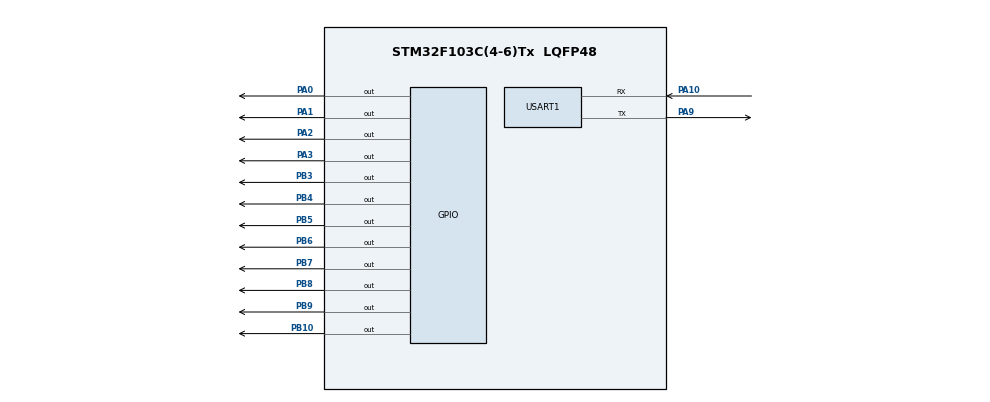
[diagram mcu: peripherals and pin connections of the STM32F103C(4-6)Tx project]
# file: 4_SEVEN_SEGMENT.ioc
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Mcu.Family=STM32F1
Mcu.Name=STM32F103C(4-6)Tx
Mcu.Package=LQFP48
NVIC.PriorityGroup=NVIC_PRIORITYGROUP_4
PA0-WKUP.Signal=GPIO_Output
PA1.Signal=GPIO_Output
PA10.Mode=Asynchronous
PA10.Signal=USART1_RX
PA2.Signal=GPIO_Output
PA3.Signal=GPIO_Output
PA9.Mode=Asynchronous
PA9.Signal=USART1_TX
PB10.Signal=GPIO_Output
PB3.Signal=GPIO_Output
PB4.Signal=GPIO_Output
PB5.Signal=GPIO_Output
PB6.Signal=GPIO_Output
PB7.Signal=GPIO_Output
PB8.Signal=GPIO_Output
PB9.Signal=GPIO_Output
PD0-OSC_IN.Mode=HSE-External-Oscillator
PD0-OSC_IN.Signal=RCC_OSC_IN
PD1-OSC_OUT.Mode=HSE-External-Oscillator
PD1-OSC_OUT.Signal=RCC_OSC_OUT
ProjectManager.HeapSize=0x200
ProjectManager.StackSize=0x400
ProjectManager.TargetToolchain=STM32CubeIDE
RCC.APB1Freq_Value=8000000
RCC.APB2Freq_Value=8000000
USART1.VirtualMode=VM_ASYNC
board=custom

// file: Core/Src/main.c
/* USER CODE BEGIN Header */
/**
  ******************************************************************************
  * @file           : main.c
  * @brief          : Main program body
  ******************************************************************************
  * @attention
  *
  * Copyright (c) 2023 STMicroelectronics.
  * All rights reserved.
  *
  * This software is licensed under terms that can be found in the LICENSE file
  * in the root directory of this software component.
  * If no LICENSE file comes with this software, it is provided AS-IS.
  *
  ******************************************************************************
  */
/* USER CODE END Header */
#include "main.h"

UART_HandleTypeDef huart1;

void SystemClock_Config(void);
static void MX_GPIO_Init(void);
static void MX_USART1_UART_Init(void);

int main(void)
{

  /* MCU Configuration--------------------------------------------------------*/

  /* Reset of all peripherals, Initializes the Flash interface and the Systick. */
  HAL_Init();

  /* USER CODE BEGIN Init */
/*
  GPIO_InitTypeDef GPIO_InitStruct;
      __HAL_RCC_GPIOA_CLK_ENABLE();
      __HAL_RCC_GPIOB_CLK_ENABLE();
      GPIO_InitStruct.Pin = GPIO_PIN_0 | GPIO_PIN_1 | GPIO_PIN_2 | GPIO_PIN_3;
      GPIO_InitStruct.Mode = GPIO_MODE_OUTPUT_PP;
      GPIO_InitStruct.Speed = GPIO_SPEED_FREQ_HIGH;
      HAL_GPIO_Init(GPIOA, &GPIO_InitStruct);
      GPIO_InitStruct.Pin = GPIO_PIN_3 | GPIO_PIN_4 | GPIO_PIN_5 | GPIO_PIN_6
              | GPIO_PIN_7 | GPIO_PIN_8 | GPIO_PIN_9 | GPIO_PIN_10;
      GPIO_InitStruct.Mode = GPIO_MODE_OUTPUT_PP;
      GPIO_InitStruct.Speed = GPIO_SPEED_FREQ_HIGH;
      HAL_GPIO_Init(GPIOB, &GPIO_InitStruct);
      */
  /* USER CODE END Init */

  /* Configure the system clock */
  SystemClock_Config();

  /* Initialize all configured peripherals */
  MX_GPIO_Init();
  MX_USART1_UART_Init();

  /* Infinite loop */
  while (1)
  {
	  displayNumber(1861);
	  HAL_Delay(500);
	  //displayNumber(5678);
	  //HAL_Delay(500);

	          //displayNumber(5678);
	          //HAL_Delay(1000);
  }
}

void displayDigit(int digit, int value)
{
    switch (digit)
    {
    case 1:
        HAL_GPIO_WritePin(GPIOA, GPIO_PIN_0, GPIO_PIN_SET);
        HAL_Delay(1000);
        break;
    case 2:
        HAL_GPIO_WritePin(GPIOA, GPIO_PIN_1, GPIO_PIN_SET);
        HAL_Delay(1000);

        break;
    case 3:
        HAL_GPIO_WritePin(GPIOA, GPIO_PIN_2, GPIO_PIN_SET);
        HAL_Delay(1000);

        break;
    case 4:
        HAL_GPIO_WritePin(GPIOA, GPIO_PIN_3, GPIO_PIN_SET);
        HAL_Delay(1000);

        break;
    }
    switch (value)
    {
    case 0:
        HAL_GPIO_WritePin(GPIOB,
                GPIO_PIN_3 | GPIO_PIN_4 | GPIO_PIN_5 | GPIO_PIN_6 | GPIO_PIN_7
                        | GPIO_PIN_8, GPIO_PIN_SET);
        HAL_GPIO_WritePin(GPIOB, GPIO_PIN_9 | GPIO_PIN_10, GPIO_PIN_RESET);
        break;
    case 1:
        HAL_GPIO_WritePin(GPIOB, GPIO_PIN_4 | GPIO_PIN_5, GPIO_PIN_SET);
        HAL_GPIO_WritePin(GPIOB,
                GPIO_PIN_3 | GPIO_PIN_6 | GPIO_PIN_8 | GPIO_PIN_7 | GPIO_PIN_9
                        | GPIO_PIN_10, GPIO_PIN_RESET);
        break;
    case 2:
        HAL_GPIO_WritePin(GPIOB,
                GPIO_PIN_3 | GPIO_PIN_4 | GPIO_PIN_6 | GPIO_PIN_7 | GPIO_PIN_9,
                GPIO_PIN_SET);
        HAL_GPIO_WritePin(GPIOB, GPIO_PIN_5 | GPIO_PIN_8 | GPIO_PIN_10,
                GPIO_PIN_RESET);
        break;
    case 3:
        HAL_GPIO_WritePin(GPIOB,
                GPIO_PIN_3 | GPIO_PIN_4 | GPIO_PIN_5 | GPIO_PIN_6 | GPIO_PIN_9,
                GPIO_PIN_SET);
        HAL_GPIO_WritePin(GPIOB, GPIO_PIN_7 | GPIO_PIN_8 | GPIO_PIN_10,
                GPIO_PIN_RESET);
        break;
    case 4:
        HAL_GPIO_WritePin(GPIOB,
                GPIO_PIN_4 | GPIO_PIN_5 | GPIO_PIN_8 | GPIO_PIN_9,
                GPIO_PIN_SET);
        HAL_GPIO_WritePin(GPIOB,
                GPIO_PIN_3 | GPIO_PIN_6 | GPIO_PIN_7 | GPIO_PIN_10,
                GPIO_PIN_RESET);
        break;
    case 5:
        HAL_GPIO_WritePin(GPIOB,
                GPIO_PIN_3 | GPIO_PIN_5 | GPIO_PIN_6 | GPIO_PIN_8 | GPIO_PIN_9,
                GPIO_PIN_SET);
        HAL_GPIO_WritePin(GPIOB, GPIO_PIN_4 | GPIO_PIN_7 | GPIO_PIN_10,
                GPIO_PIN_RESET);
        break;
    case 6:
        HAL_GPIO_WritePin(GPIOB,
                GPIO_PIN_5 | GPIO_PIN_3 | GPIO_PIN_6 | GPIO_PIN_7 | GPIO_PIN_8
                        | GPIO_PIN_9, GPIO_PIN_SET);
        HAL_GPIO_WritePin(GPIOB, GPIO_PIN_4 | GPIO_PIN_10, GPIO_PIN_RESET);
        break;
    case 7:
        HAL_GPIO_WritePin(GPIOB,
                GPIO_PIN_3 | GPIO_PIN_4 | GPIO_PIN_5 | GPIO_PIN_8,
                GPIO_PIN_SET);
        HAL_GPIO_WritePin(GPIOB,
                GPIO_PIN_6 | GPIO_PIN_7 | GPIO_PIN_9 | GPIO_PIN_10,
                GPIO_PIN_RESET);
        break;
    case 8:
        HAL_GPIO_WritePin(GPIOB,
                GPIO_PIN_3 | GPIO_PIN_4 | GPIO_PIN_5 | GPIO_PIN_6 | GPIO_PIN_7
                        | GPIO_PIN_8 | GPIO_PIN_9, GPIO_PIN_SET);
        HAL_GPIO_WritePin(GPIOB, GPIO_PIN_10, GPIO_PIN_RESET);
        break;
    case 9:
        HAL_GPIO_WritePin(GPIOB,
                GPIO_PIN_3 | GPIO_PIN_4 | GPIO_PIN_5 | GPIO_PIN_6 | GPIO_PIN_8
                        | GPIO_PIN_9, GPIO_PIN_SET);
        HAL_GPIO_WritePin(GPIOB, GPIO_PIN_7 | GPIO_PIN_10, GPIO_PIN_RESET);
        break;
    }
}
void displayNumber(int number)
{
    int digit1 = number / 1000;
    int digit2 = (number / 100) % 10;
    int digit3 = (number / 10) % 10;
    int digit4 = number % 10;
    HAL_GPIO_WritePin(GPIOA, GPIO_PIN_0,
            GPIO_PIN_RESET);
    displayDigit(1, digit1);
    HAL_Delay(1000);
    HAL_GPIO_WritePin(GPIOA, GPIO_PIN_0 | GPIO_PIN_1 | GPIO_PIN_2 | GPIO_PIN_3,
            GPIO_PIN_RESET);
    displayDigit(2, digit2);
    HAL_Delay(1000);
    HAL_GPIO_WritePin(GPIOA, GPIO_PIN_0 | GPIO_PIN_1 | GPIO_PIN_2 | GPIO_PIN_3,
            GPIO_PIN_RESET);
    displayDigit(3, digit3);
    HAL_Delay(1000);
    HAL_GPIO_WritePin(GPIOA, GPIO_PIN_0 | GPIO_PIN_1 | GPIO_PIN_2 | GPIO_PIN_3,
            GPIO_PIN_RESET);
    displayDigit(4, digit4);
    HAL_Delay(1000);
}

void SystemClock_Config(void)
{
  RCC_OscInitTypeDef RCC_OscInitStruct = {0};
  RCC_ClkInitTypeDef RCC_ClkInitStruct = {0};

  /** Initializes the RCC Oscillators according to the specified parameters
  * in the RCC_OscInitTypeDef structure.
  */
  RCC_OscInitStruct.OscillatorType = RCC_OSCILLATORTYPE_HSI;
  RCC_OscInitStruct.HSIState = RCC_HSI_ON;
  RCC_OscInitStruct.HSICalibrationValue = RCC_HSICALIBRATION_DEFAULT;
  RCC_OscInitStruct.PLL.PLLState = RCC_PLL_NONE;
  if (HAL_RCC_OscConfig(&RCC_OscInitStruct) != HAL_OK)
  {
    Error_Handler();
  }

  /** Initializes the CPU, AHB and APB buses clocks
  */
  RCC_ClkInitStruct.ClockType = RCC_CLOCKTYPE_HCLK|RCC_CLOCKTYPE_SYSCLK
                              |RCC_CLOCKTYPE_PCLK1|RCC_CLOCKTYPE_PCLK2;
  RCC_ClkInitStruct.SYSCLKSource = RCC_SYSCLKSOURCE_HSI;
  RCC_ClkInitStruct.AHBCLKDivider = RCC_SYSCLK_DIV1;
  RCC_ClkInitStruct.APB1CLKDivider = RCC_HCLK_DIV1;
  RCC_ClkInitStruct.APB2CLKDivider = RCC_HCLK_DIV1;

  if (HAL_RCC_ClockConfig(&RCC_ClkInitStruct, FLASH_LATENCY_0) != HAL_OK)
  {
    Error_Handler();
  }
}

static void MX_USART1_UART_Init(void)
{

  huart1.Instance = USART1;
  huart1.Init.BaudRate = 115200;
  huart1.Init.WordLength = UART_WORDLENGTH_8B;
  huart1.Init.StopBits = UART_STOPBITS_1;
  huart1.Init.Parity = UART_PARITY_NONE;
  huart1.Init.Mode = UART_MODE_TX_RX;
  huart1.Init.HwFlowCtl = UART_HWCONTROL_NONE;
  huart1.Init.OverSampling = UART_OVERSAMPLING_16;
  if (HAL_UART_Init(&huart1) != HAL_OK)
  {
    Error_Handler();
  }

}

static void MX_GPIO_Init(void)
{
  GPIO_InitTypeDef GPIO_InitStruct = {0};

  /* GPIO Ports Clock Enable */
  __HAL_RCC_GPIOD_CLK_ENABLE();
  __HAL_RCC_GPIOA_CLK_ENABLE();
  __HAL_RCC_GPIOB_CLK_ENABLE();

  /*Configure GPIO pin Output Level */
  HAL_GPIO_WritePin(GPIOA, GPIO_PIN_0|GPIO_PIN_1|GPIO_PIN_2|GPIO_PIN_3, GPIO_PIN_RESET);

  /*Configure GPIO pin Output Level */
  HAL_GPIO_WritePin(GPIOB, GPIO_PIN_10|GPIO_PIN_3|GPIO_PIN_4|GPIO_PIN_5
                          |GPIO_PIN_6|GPIO_PIN_7|GPIO_PIN_8|GPIO_PIN_9, GPIO_PIN_RESET);

  /*Configure GPIO pins : PA0 PA1 PA2 PA3 */
  GPIO_InitStruct.Pin = GPIO_PIN_0|GPIO_PIN_1|GPIO_PIN_2|GPIO_PIN_3;
  GPIO_InitStruct.Mode = GPIO_MODE_OUTPUT_PP;
  GPIO_InitStruct.Pull = GPIO_NOPULL;
  GPIO_InitStruct.Speed = GPIO_SPEED_FREQ_LOW;
  HAL_GPIO_Init(GPIOA, &GPIO_InitStruct);

  /*Configure GPIO pins : PB10 PB3 PB4 PB5
                           PB6 PB7 PB8 PB9 */
  GPIO_InitStruct.Pin = GPIO_PIN_10|GPIO_PIN_3|GPIO_PIN_4|GPIO_PIN_5
                          |GPIO_PIN_6|GPIO_PIN_7|GPIO_PIN_8|GPIO_PIN_9;
  GPIO_InitStruct.Mode = GPIO_MODE_OUTPUT_PP;
  GPIO_InitStruct.Pull = GPIO_NOPULL;
  GPIO_InitStruct.Speed = GPIO_SPEED_FREQ_LOW;
  HAL_GPIO_Init(GPIOB, &GPIO_InitStruct);

}

void Error_Handler(void)
{
  __disable_irq();
  while (1)
  {
  }
}
